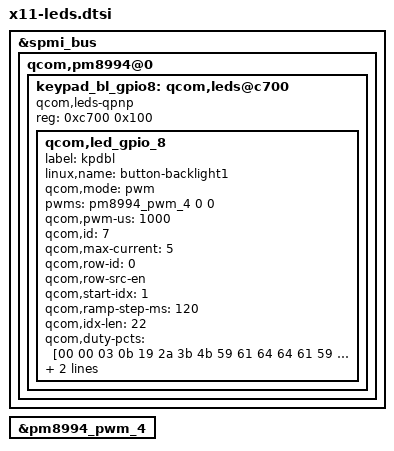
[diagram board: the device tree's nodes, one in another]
/* Copyright (c) 2017, The Linux Foundation. All rights reserved.
 *
 * This program is free software; you can redistribute it and/or modify
 * it under the terms of the GNU General Public License version 2 and
 * only version 2 as published by the Free Software Foundation.
 *
 * This program is distributed in the hope that it will be useful,
 * but WITHOUT ANY WARRANTY; without even the implied warranty of
 * MERCHANTABILITY or FITNESS FOR A PARTICULAR PURPOSE.  See the
 * GNU General Public License for more details.
 */

&spmi_bus {
    qcom,pm8994@0 {
		keypad_bl_gpio8: qcom,leds@c700 {
			compatible = "qcom,leds-qpnp";
			reg = <0xc700 0x100>;
			status = "okay";
			qcom,led_gpio_8 {
				label = "kpdbl";
				linux,name = "button-backlight1";
				qcom,mode = "pwm";
				pwms = <&pm8994_pwm_4 0 0>;
				qcom,pwm-us = <1000>;
				qcom,id = <7>;
				qcom,max-current = <5>;
				qcom,row-id = <0>;
				qcom,row-src-en;
				qcom,start-idx = <1>;
				qcom,ramp-step-ms = <120>;
				qcom,idx-len = <22>;
				qcom,duty-pcts = [00
						00 03 0b 19 2a
						3b 4b 59 61 64
						64 61 59 4b 3b
						2a 19 0b 03 00
						00];
				qcom,use-blink;
				qcom,in-order-command-processing;
			};
		};
    };
};

&pm8994_pwm_4 {
	status = "okay";
};
